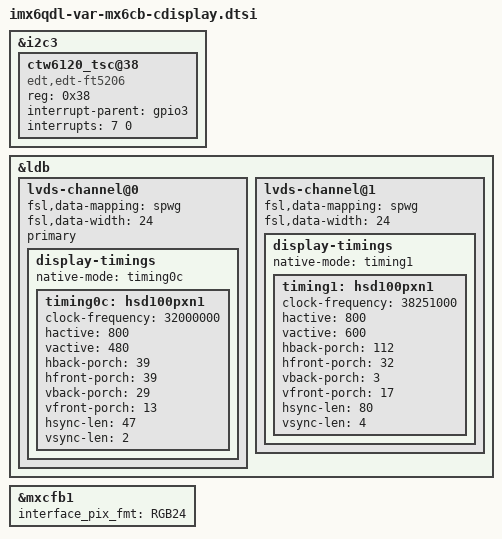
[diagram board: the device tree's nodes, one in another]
/*
 * Copyright (C) 2015-2017 Variscite Ltd.
 *
 * This program is free software; you can redistribute it and/or modify
 * it under the terms of the GNU General Public License version 2 as
 * published by the Free Software Foundation.
 *
 * Capacitive Display for VAR-MX6CustomBoard
 */

&i2c3 {
	/* Touch */
	ctw6120_tsc@38 {
		compatible = "edt,edt-ft5206";
		reg = <0x38>;
		interrupt-parent = <&gpio3>;
		interrupts = <7 0>;
	};
};

&ldb {
	status = "okay";

	lvds-channel@0 {
		fsl,data-mapping = "spwg";
		fsl,data-width = <24>;
		status = "okay";
		primary;

		display-timings {
			native-mode = <&timing0c>;
			timing0c: hsd100pxn1 {
				clock-frequency = <32000000>;
				hactive = <800>;
				vactive = <480>;
				hback-porch = <39>;
				hfront-porch = <39>;
				vback-porch = <29>;
				vfront-porch = <13>;
				hsync-len = <47>;
				vsync-len = <2>;
			};
		};
	};

	lvds-channel@1 {
		fsl,data-mapping = "spwg";
		fsl,data-width = <24>;
		status = "okay";

		display-timings {
			native-mode = <&timing1>;
			timing1: hsd100pxn1 {
				clock-frequency = <38251000>;
				hactive = <800>;
				vactive = <600>;
				hback-porch = <112>;
				hfront-porch = <32>;
				vback-porch = <3>;
				vfront-porch = <17>;
				hsync-len = <80>;
				vsync-len = <4>;
			};
		};
	};
};

&mxcfb1 {
	interface_pix_fmt = "RGB24";
};
